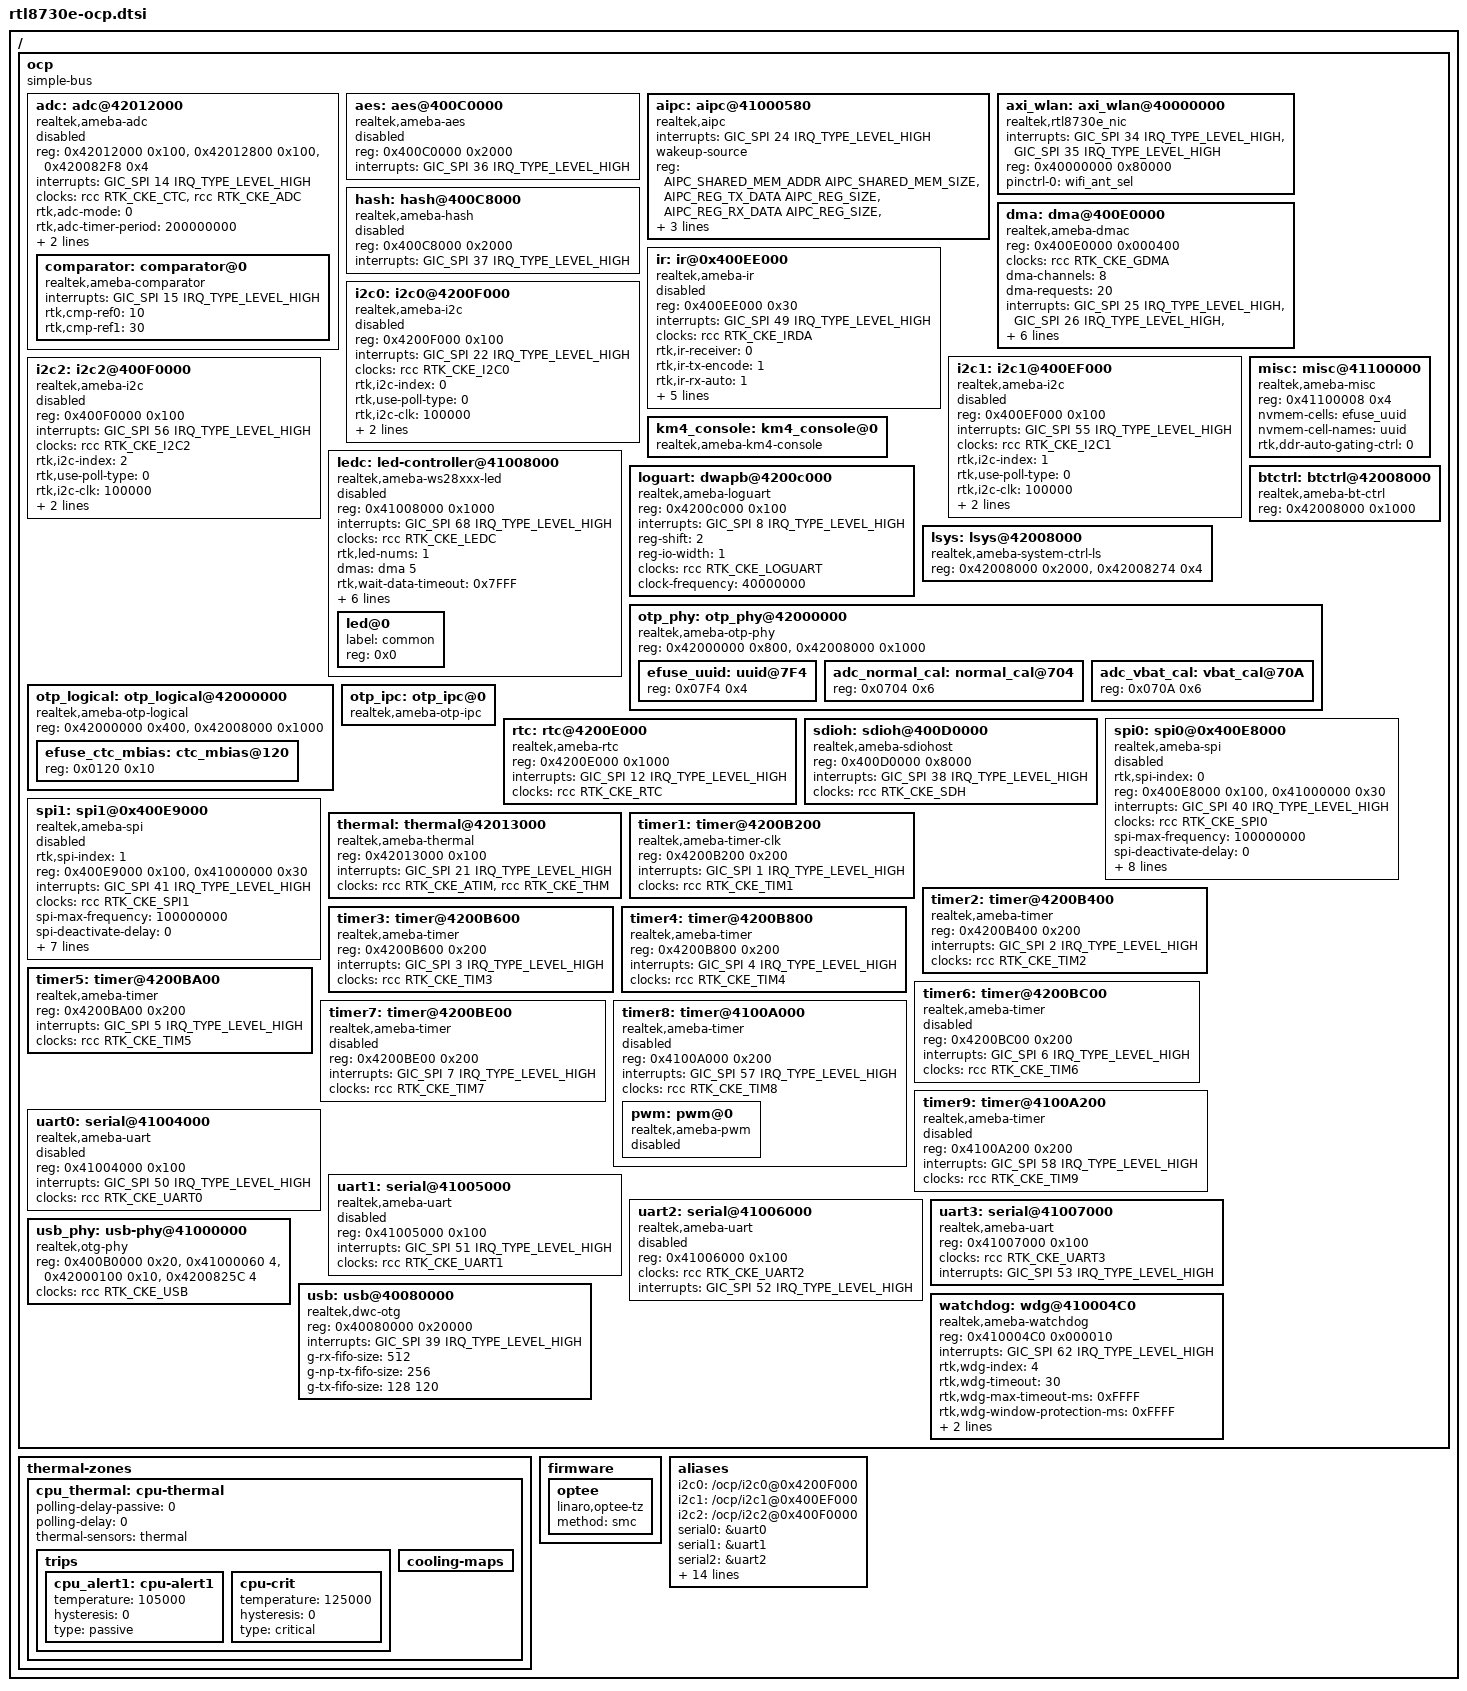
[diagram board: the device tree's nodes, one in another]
// SPDX-License-Identifier: GPL-2.0-only
/*
* Realtek DTS for on-chip peripherals
*
* Copyright (C) 2023, Realtek Corporation. All rights reserved.
*/

#include <dt-bindings/interrupt-controller/irq.h>
#include <dt-bindings/realtek/ameba_ipc/ameba_ipc_resource.h>
#include <dt-bindings/realtek/clock/realtek-ameba-clock.h>

#include "rtl8730e-rcc.dtsi"
#include "rtl8730e-pinctrl.dtsi"
#include "rtl8730e-audio.dtsi"

/ {
	ocp {
		compatible = "simple-bus";
		#address-cells = <1>;
		#size-cells = <1>;
		ranges;

		adc: adc@42012000 {
			compatible = "realtek,ameba-adc";
			#io-channel-cells = <1>;
			reg = <0x42012000 0x100>,
				<0x42012800 0x100>,
				<0x420082F8 0x4>;//Control digital path input for ADC and CTC pad
			interrupts = <GIC_SPI 14 IRQ_TYPE_LEVEL_HIGH>;
			clocks = <&rcc RTK_CKE_CTC>, <&rcc RTK_CKE_ADC>;
			clock-names = "rtk_ctc_clk", "rtk_adc_clk";
			rtk,adc-mode = <0>; // 0: Software-trigger mode, 1: Automatic mode, 2: Timer-trigger mode
			rtk,adc-timer-period = <200000000>; // Useful only in timer-trigger mode. Unit: ns. Range: 100ms~2s
			//rtk,adc-channels = <0>, <1>, <2>, <6>;
			//rtk,adc-diff-channels = <4 5>;
			nvmem-cells = <&adc_normal_cal>, <&adc_vbat_cal>;
			nvmem-cell-names = "normal_cal", "vbat_cal";
			status = "disabled";

			comparator: comparator@0 {
				compatible = "realtek,ameba-comparator";
				interrupts = <GIC_SPI 15 IRQ_TYPE_LEVEL_HIGH>;
				rtk,cmp-ref0 = <10>;
				rtk,cmp-ref1 = <30>;
			};
		};

		aes: aes@400C0000 {
			compatible = "realtek,ameba-aes";
			reg = <0x400C0000 0x2000>;
			interrupts = <GIC_SPI 36 IRQ_TYPE_LEVEL_HIGH>;
			status = "disabled";
		};

		aipc: aipc@41000580 {
			compatible = "realtek,aipc";
			interrupts = <GIC_SPI 24 IRQ_TYPE_LEVEL_HIGH>;
			wakeup-source;
			reg = <AIPC_SHARED_MEM_ADDR AIPC_SHARED_MEM_SIZE>, // res 0
				<AIPC_REG_TX_DATA AIPC_REG_SIZE>, // res 1
				<AIPC_REG_RX_DATA AIPC_REG_SIZE>, // res 2
				<AIPC_REG_ISR AIPC_REG_SIZE>, // res 3
				<AIPC_REG_IMR AIPC_REG_SIZE>, // res 4
				<AIPC_REG_ICR AIPC_REG_SIZE>; // res 5
		};

		axi_wlan: axi_wlan@40000000 {
			compatible = "realtek,rtl8730e_nic";
			interrupts = <GIC_SPI 34 IRQ_TYPE_LEVEL_HIGH>,
				<GIC_SPI 35 IRQ_TYPE_LEVEL_HIGH>;
			reg = <0x40000000 0x80000>; // wifi register base address and length
			pinctrl-names = "default";
			pinctrl-0 = <&wifi_ant_sel>;
		};

		dma: dma@400E0000 {
			compatible = "realtek,ameba-dmac";
			reg = <0x400E0000 0x000400>;
			clocks = <&rcc RTK_CKE_GDMA>;
			#dma-cells = <1>;
			dma-channels = <8>;
			dma-requests = <20>;
			interrupts = <GIC_SPI 25 IRQ_TYPE_LEVEL_HIGH>,
						<GIC_SPI 26 IRQ_TYPE_LEVEL_HIGH>,
						<GIC_SPI 27 IRQ_TYPE_LEVEL_HIGH>,
						<GIC_SPI 28 IRQ_TYPE_LEVEL_HIGH>,
						<GIC_SPI 29 IRQ_TYPE_LEVEL_HIGH>,
						<GIC_SPI 30 IRQ_TYPE_LEVEL_HIGH>,
						<GIC_SPI 31 IRQ_TYPE_LEVEL_HIGH>,
						<GIC_SPI 32 IRQ_TYPE_LEVEL_HIGH>;
		};

		hash: hash@400C8000 {
			compatible = "realtek,ameba-hash";
			reg = <0x400C8000 0x2000>;
			interrupts = <GIC_SPI 37 IRQ_TYPE_LEVEL_HIGH>;
			status = "disabled";
		};

		ir: ir@0x400EE000 {
			compatible = "realtek,ameba-ir";
			reg = <0x400EE000 0x30>;
			interrupts = <GIC_SPI 49 IRQ_TYPE_LEVEL_HIGH>;
			clocks = <&rcc RTK_CKE_IRDA>;
			rtk,ir-receiver = <0>; // 0: tx only; 1: rx only.
			rtk,ir-tx-encode = <1>; // based on tx only. nec encode, usually open = 1.
			rtk,ir-rx-auto = <1>; // 0: can reject rx; 1: auto rx whenever data arrived.
			rtk,ir-cnt-thred-type = <1>; // 0: low level; 1: high level.
			rtk,ir-cnt-threshold = <30000>; // If hw receive no data for 30ms(set 30000 here), represents the end.
			rtk,ir-rx-trigger-mode = <0>; // 0: fall edge; 1: rising edge; 2: both.
			rtk,ir-idle-level = <0>; // 0: low level; 1: high level.
			rtk,ir_rx_inverse = <0>; // 0: do not need software inverse; 1: need software inverse
			status = "disabled";
		};

		i2c0: i2c0@4200F000 {
			compatible = "realtek,ameba-i2c";
			reg = <0x4200F000 0x100>;
			interrupts = <GIC_SPI 22 IRQ_TYPE_LEVEL_HIGH>;
			clocks = <&rcc RTK_CKE_I2C0>;
			rtk,i2c-index = <0>;
			rtk,use-poll-type = <0>;
			rtk,i2c-clk = <100000>;
			rtk,wait-timeout = <0x7D0>;
			rtk,i2c-reg-slave-num = <0>;
			status = "disabled";
		};

		i2c1: i2c1@400EF000 {
			compatible = "realtek,ameba-i2c";
			reg = <0x400EF000 0x100>;
			interrupts = <GIC_SPI 55 IRQ_TYPE_LEVEL_HIGH>;
			clocks = <&rcc RTK_CKE_I2C1>;
			rtk,i2c-index = <1>;
			rtk,use-poll-type = <0>;
			rtk,i2c-clk = <100000>;
			rtk,wait-timeout = <0x7D0>;
			rtk,i2c-reg-slave-num = <0>;
			status = "disabled";
		};

		i2c2: i2c2@400F0000 {
			compatible = "realtek,ameba-i2c";
			reg = <0x400F0000 0x100>;
			interrupts = <GIC_SPI 56 IRQ_TYPE_LEVEL_HIGH>;
			clocks = <&rcc RTK_CKE_I2C2>;
			rtk,i2c-index = <2>;
			rtk,use-poll-type = <0>;
			rtk,i2c-clk = <100000>;
			rtk,wait-timeout = <0x7D0>;
			rtk,i2c-reg-slave-num = <0>;
			status = "disabled";
		};

		km4_console: km4_console@0 {
			compatible = "realtek,ameba-km4-console";
		};

		ledc: led-controller@41008000 {
			compatible = "realtek,ameba-ws28xxx-led";
			reg = <0x41008000 0x1000>;
			interrupts = <GIC_SPI 68 IRQ_TYPE_LEVEL_HIGH>;
			#address-cells = <1>;
			#size-cells = <0>;
			clocks = <&rcc RTK_CKE_LEDC>;
			rtk,led-nums = <1>;
			dmas = <&dma 5>;
			dma-names = "dma_leds_tx";
			rtk,wait-data-timeout = <0x7FFF>;
			rtk,output-RGB-mode = <0>; // Refer to spec for details.
			rtk,data-tx-time0h = <0xD>;
			rtk,data-tx-time0l = <0x27>;
			rtk,data-tx-time1h = <0x27>;
			rtk,data-tx-time1l = <0xD>;
			rtk,refresh-time = <0x3A97>;
			status = "disabled";

			led@0 {
				label = "common";
				reg = <0x0>;
			};
		};

		loguart: dwapb@4200c000 {
			compatible = "realtek,ameba-loguart";
			reg = <0x4200c000 0x100>;
			interrupts = <GIC_SPI 8 IRQ_TYPE_LEVEL_HIGH>;
			reg-shift = <2>;
			reg-io-width = <1>;
			clocks = <&rcc RTK_CKE_LOGUART>;
			clock-frequency = <40000000>;
		};

		lsys: lsys@42008000 {
			compatible = "realtek,ameba-system-ctrl-ls";
			reg = <0x42008000 0x2000>,
				<0x42008274 0x4>;
		};

		misc: misc@41100000 {
			compatible = "realtek,ameba-misc";
			reg = <0x41100008 0x4>;
			nvmem-cells = <&efuse_uuid>;
			nvmem-cell-names = "uuid";
			rtk,ddr-auto-gating-ctrl = <0>;
			status = "okay";
		};

		btctrl: btctrl@42008000 {
			compatible = "realtek,ameba-bt-ctrl";
			reg = <0x42008000 0x1000>;
		};


		otp_phy: otp_phy@42000000 {
			compatible = "realtek,ameba-otp-phy";
			#address-cells = <1>;
			#size-cells = <0>;
			reg = <0x42000000 0x800>,
				<0x42008000 0x1000>;

			efuse_uuid: uuid@7F4 {
				reg = <0x07F4 0x4>;
			};

			adc_normal_cal: normal_cal@704 {
				reg = <0x0704 0x6>;
			};

			adc_vbat_cal: vbat_cal@70A {
				reg = <0x070A 0x6>;
			};
		};

		otp_logical: otp_logical@42000000 {
			compatible = "realtek,ameba-otp-logical";
			reg = <0x42000000 0x400>,
				<0x42008000 0x1000>;

			efuse_ctc_mbias: ctc_mbias@120 {
				reg = <0x0120 0x10>;
			};
		};

		otp_ipc: otp_ipc@0 {
			compatible = "realtek,ameba-otp-ipc";
		};

		rtc: rtc@4200E000 {
			compatible = "realtek,ameba-rtc";
			reg = <0x4200E000 0x1000>;
			interrupts = <GIC_SPI 12 IRQ_TYPE_LEVEL_HIGH>;
			clocks = <&rcc RTK_CKE_RTC>;
		};

		sdioh: sdioh@400D0000 {
			compatible = "realtek,ameba-sdiohost";
			reg = <0x400D0000 0x8000>;
			interrupts = <GIC_SPI 38 IRQ_TYPE_LEVEL_HIGH>;
			clocks = <&rcc RTK_CKE_SDH>;
			status = "okay";
		};

		spi0: spi0@0x400E8000 {
			compatible = "realtek,ameba-spi";
			rtk,spi-index = <0>;
			reg = <0x400E8000 0x100>,
					<0x41000000 0x30>; // reg base for spi role setting.
			interrupts = <GIC_SPI 40 IRQ_TYPE_LEVEL_HIGH>;
			clocks = <&rcc RTK_CKE_SPI0>;
			clock-names = "rtk_spi_clk";
			spi-max-frequency = <100000000>;
			spi-deactivate-delay = <0>;
			rtk,spi-for-kernel = <0>;
			rtk,spi-slave-mode = <0>;
			rtk,spi-dma-en = <0>;
			dmas = <&dma 16>,<&dma 17>;
			dma-names = "spi0-tx","spi0-rx";
			rtk,spi-master-poll-mode = <0>;
			rtk,spi-default-cs = <0>;
			rtk,max-cs-num = <2>;
			//only master mode set SPI_CS to GPIO, so spi0_pins only set SPI0_CLK, SPI0_MOSI and SPI0_MISO.
			rtk,spi-cs-gpios = <&gpiob 17 0>;
			status = "disabled";
		};

		spi1: spi1@0x400E9000 {
			compatible = "realtek,ameba-spi";
			rtk,spi-index = <1>;
			reg = <0x400E9000 0x100>,
					<0x41000000 0x30>; // reg base for spi role setting.
			interrupts = <GIC_SPI 41 IRQ_TYPE_LEVEL_HIGH>;
			clocks = <&rcc RTK_CKE_SPI1>;
			clock-names = "rtk_spi_clk";
			spi-max-frequency = <100000000>;
			spi-deactivate-delay = <0>;
			rtk,spi-for-kernel = <0>;
			rtk,spi-slave-mode = <1>;
			rtk,spi-dma-en = <0>;
			dmas = <&dma 18>,<&dma 19>;
			dma-names = "spi1-tx","spi1-rx";
			rtk,spi-master-poll-mode = <0>;
			rtk,spi-default-cs = <0>;
			rtk,max-cs-num = <2>;
			//rtk,spi-cs-gpios = <&gpioa 2 0>;//only master mode set SPI_CS to GPIO.
			status = "disabled";
		};

		thermal: thermal@42013000 {
			compatible = "realtek,ameba-thermal";
			reg = <0x42013000 0x100>;
			interrupts = <GIC_SPI 21 IRQ_TYPE_LEVEL_HIGH>; // use timer7, MP chip: 21
			clocks = <&rcc RTK_CKE_ATIM>, <&rcc RTK_CKE_THM>;
			clock-names = "rtk_aon_tim_clk", "rtk_thermal_clk";
			#thermal-sensor-cells = <0>;
		};

		timer1: timer@4200B200 {
			compatible = "realtek,ameba-timer-clk";
			reg = <0x4200B200 0x200>;
			interrupts = <GIC_SPI 1 IRQ_TYPE_LEVEL_HIGH>;
			clocks = <&rcc RTK_CKE_TIM1>;
		};

		timer2: timer@4200B400 {
			compatible = "realtek,ameba-timer";
			reg = <0x4200B400 0x200>;
			interrupts = <GIC_SPI 2 IRQ_TYPE_LEVEL_HIGH>;
			clocks = <&rcc RTK_CKE_TIM2>;
		};

		timer3: timer@4200B600 {
			compatible = "realtek,ameba-timer";
			reg = <0x4200B600 0x200>;
			interrupts = <GIC_SPI 3 IRQ_TYPE_LEVEL_HIGH>;
			clocks = <&rcc RTK_CKE_TIM3>;
		};

		timer4: timer@4200B800 {
			compatible = "realtek,ameba-timer";
			reg = <0x4200B800 0x200>;
			interrupts = <GIC_SPI 4 IRQ_TYPE_LEVEL_HIGH>;
			clocks = <&rcc RTK_CKE_TIM4>;
		};

		timer5: timer@4200BA00 {
			compatible = "realtek,ameba-timer";
			reg = <0x4200BA00 0x200>;
			interrupts = <GIC_SPI 5 IRQ_TYPE_LEVEL_HIGH>;
			clocks = <&rcc RTK_CKE_TIM5>;
		};

		timer6: timer@4200BC00 {
			compatible = "realtek,ameba-timer";
			reg = <0x4200BC00 0x200>;
			interrupts = <GIC_SPI 6 IRQ_TYPE_LEVEL_HIGH>;
			clocks = <&rcc RTK_CKE_TIM6>;
			status = "disabled";
		};

		timer7: timer@4200BE00 {
			compatible = "realtek,ameba-timer";
			reg = <0x4200BE00 0x200>;
			interrupts = <GIC_SPI 7 IRQ_TYPE_LEVEL_HIGH>;
			clocks = <&rcc RTK_CKE_TIM7>;
			status = "disabled";
		};

		timer8: timer@4100A000 {
			compatible = "realtek,ameba-timer";
			reg = <0x4100A000 0x200>;
			interrupts = <GIC_SPI 57 IRQ_TYPE_LEVEL_HIGH>;
			clocks = <&rcc RTK_CKE_TIM8>;
			status = "disabled";

			pwm: pwm@0 {
				compatible = "realtek,ameba-pwm";
				status = "disabled";
			};
		};

		// Cannot be enabled simultaneously with captimer node
		timer9: timer@4100A200 {
			compatible = "realtek,ameba-timer";
			reg = <0x4100A200 0x200>;
			interrupts = <GIC_SPI 58 IRQ_TYPE_LEVEL_HIGH>;
			clocks = <&rcc RTK_CKE_TIM9>;
			status = "disabled";
		};

		uart0: serial@41004000 {
			compatible = "realtek,ameba-uart";
			reg = <0x41004000 0x100>;
			interrupts = <GIC_SPI 50 IRQ_TYPE_LEVEL_HIGH>;
			clocks = <&rcc RTK_CKE_UART0>;
			status = "disabled";
		};

		uart1: serial@41005000 {
			compatible = "realtek,ameba-uart";
			reg = <0x41005000 0x100>;
			interrupts = <GIC_SPI 51 IRQ_TYPE_LEVEL_HIGH>;
			clocks = <&rcc RTK_CKE_UART1>;
			status = "disabled";
		};

		uart2: serial@41006000 {
			compatible = "realtek,ameba-uart";
			reg = <0x41006000 0x100>;
			clocks = <&rcc RTK_CKE_UART2>;
			interrupts = <GIC_SPI 52 IRQ_TYPE_LEVEL_HIGH>;
			status = "disabled";
		};

		uart3: serial@41007000 {
			compatible = "realtek,ameba-uart";
			reg = <0x41007000 0x100>;
			clocks = <&rcc RTK_CKE_UART3>;
			interrupts = <GIC_SPI 53 IRQ_TYPE_LEVEL_HIGH>;
		};

		usb_phy: usb-phy@41000000 {
			compatible = "realtek,otg-phy";
			reg = <0x400B0000 0x20>,
				<0x41000060 4>,
				<0x42000100 0x10>,
				<0x4200825C 4>;
			#phy-cells = <0>;
			clocks = <&rcc RTK_CKE_USB>;
			status = "okay";
		};

		usb: usb@40080000 {
			compatible = "realtek,dwc-otg";
			reg = <0x40080000 0x20000>;
			interrupts = <GIC_SPI 39 IRQ_TYPE_LEVEL_HIGH>;
			g-rx-fifo-size = <512>;
			g-np-tx-fifo-size = <256>;
			g-tx-fifo-size = <128 120>;
			status = "okay";
		};

		// Watchdog4 is non-secure for linux system.
		watchdog: wdg@410004C0 {
			compatible = "realtek,ameba-watchdog";
			reg = <0x410004C0 0x000010>;
			interrupts = <GIC_SPI 62 IRQ_TYPE_LEVEL_HIGH>;
			rtk,wdg-index = <4>;
			rtk,wdg-timeout = <30>; // seconds
			rtk,wdg-max-timeout-ms = <0xFFFF>; // 1~0xFFFF
			rtk,wdg-window-protection-ms = <0xFFFF>; // 0xFFFF means disabled, usually: disabled.
			rtk,wdg-int-trigger-threshold-ms = <50>;
			rtk,wdg-interrupt-mode = <1>;
		};
	};

	thermal-zones {
		cpu_thermal: cpu-thermal {
			polling-delay-passive = <0>;
			polling-delay = <0>;
			thermal-sensors = <&thermal>;

			trips {
				cpu_alert1: cpu-alert1 {
					temperature = <105000>;
					hysteresis = <0>;
					type = "passive";
				};
				cpu-crit {
					temperature = <125000>;
					hysteresis = <0>;
					type = "critical";
				};
			};

			cooling-maps {
			};
		};
	};

	firmware {
		optee {
			compatible = "linaro,optee-tz";
			method = "smc";
		};
	};

	aliases {
		i2c0 = "/ocp/i2c0@0x4200F000";
		i2c1 = "/ocp/i2c1@0x400EF000";
		i2c2 = "/ocp/i2c2@0x400F0000";
		serial0 = &uart0;
		serial1 = &uart1;
		serial2 = &uart2;
		serial3 = &uart3;
		spic = "/ocp/spi@44000000";
		spi0 = "/ocp/spi0@0x400E8000";
		spi1 = "/ocp/spi1@0x400E9000";
		tim1 = &timer1;
		tim2 = &timer2;
		tim3 = &timer3;
		tim4 = &timer4;
		tim5 = &timer5;
		tim6 = &timer6;
		tim7 = &timer7;
		tim8 = &timer8;
		tim9 = &timer9;
		watchdog0 = "/ocp/wdg0@0x410004C0";
	};
};
